# Spirit3 register map
File version: 1.0
CPU: CM0+ r0p0, little endian, no MPU, no FPU, 2 interrupt priority bits
Registers are 32-bit, read-write, reset 0x0 unless marked. A register's access mark holds for its fields unless they carry their own. Offsets are from the block's base; [hi:lo] are bit positions.

## BUBBLE_RF
Base 0x49001000
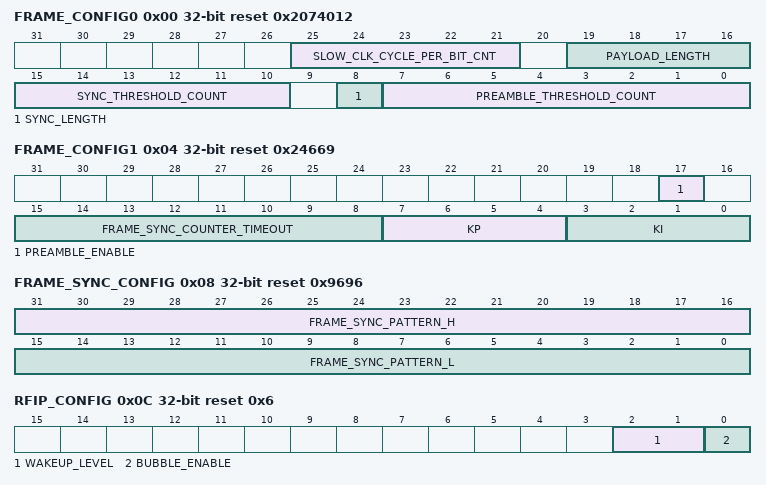
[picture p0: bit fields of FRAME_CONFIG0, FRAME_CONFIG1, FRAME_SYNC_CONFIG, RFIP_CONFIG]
0x00 FRAME_CONFIG0 reset 0x2074012
  [25:21] SLOW_CLK_CYCLE_PER_BIT_CNT — The number of expected slow clock cycle per each manchester coded bit (default 16)
  [19:16] PAYLOAD_LENGTH — The number of data Bytes in the payload (decoded)
  [15:10] SYNC_THRESHOLD_COUNT — Detection threshold when receiving the Frame sync (Manchester encoded)
  [8] SYNC_LENGTH — Frame sync pattern length
  [7:0] PREAMBLE_THRESHOLD_COUNT — the number of transitions for preamble detection when receiving the Manchester encoded preamble
0x04 FRAME_CONFIG1 reset 0x24669
  [17] PREAMBLE_ENABLE — Preamble detection enable
  [15:8] FRAME_SYNC_COUNTER_TIMEOUT — The timeout in Manchester encoded bits for the Frame Sync
  [7:4] KP — Kp is the first order gain value of the timing recovery loop
  [3:0] KI — Ki is the second order gain value of the timing recovery loop
0x08 FRAME_SYNC_CONFIG reset 0x9696
  [31:16] FRAME_SYNC_PATTERN_H — The value of the frame sync pattern, High word, Manchester encoded, used only when the frame sync length is 32 bits
  [15:0] FRAME_SYNC_PATTERN_L — The value of the frame sync pattern, Low word, Manchester encoded, used both when the frame sync length is 16 bits and 32 bits
0x0C RFIP_CONFIG reset 0x6
  [2:1] WAKEUP_LEVEL
  [0] BUBBLE_ENABLE — Enables (starts) or Disables (stops) the bubble feature
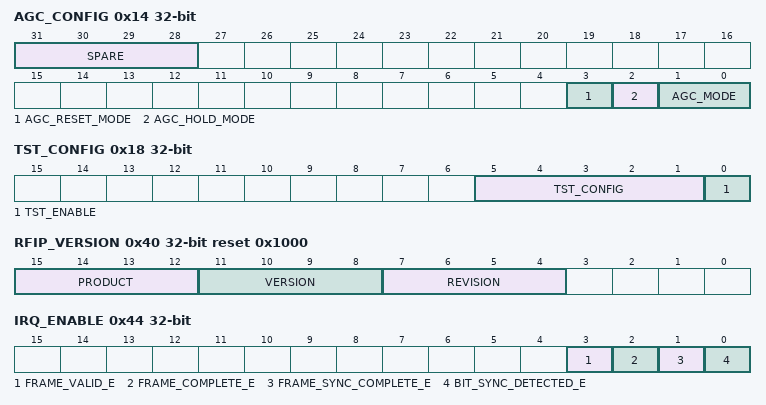
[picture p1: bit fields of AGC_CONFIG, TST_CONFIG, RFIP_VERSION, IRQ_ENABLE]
0x14 AGC_CONFIG
  [31:28] SPARE — SPARE registers
  [3] AGC_RESET_MODE — The AGC reset behavior when the AGC is working in ON or HOLD mode
  [2] AGC_HOLD_MODE — The behavior when the AGC is ON and is working in HOLD mode
  [1:0] AGC_MODE — Define the working mode of the AGC
0x18 TST_CONFIG
  [5:1] TST_CONFIG — Define which test configuration is reported in the DTB bus
  [0] TST_ENABLE — Enable (1) or Disable (0- default) the Test feature
0x1C PAYLOAD_0 ro
  [31:0] PAYLOAD_0 — First part of the payload (Least significant Byte First)
0x20 PAYLOAD_1 ro
  [31:0] PAYLOAD_1 — Second part of the payload (Least significant Byte First)
0x40 RFIP_VERSION ro reset 0x1000
  [15:12] PRODUCT — Used for major upgrades (new protocols support / new features)
  [11:8] VERSION — Version of the RFIP (to be used for cut upgrades)
  [7:4] REVISION — Revision of the RFIP to be used for metal fixes)
0x44 IRQ_ENABLE
  [3] FRAME_VALID_E — Enables interrupt on FRAME_VALID_F flag
  [2] FRAME_COMPLETE_E — Enables interrupt on FRMAE_COMPLETE_F flag
  [1] FRAME_SYNC_COMPLETE_E — Enables interrupt on FRAME_SYNC_COMPLETE_F flag
  [0] BIT_SYNC_DETECTED_E — Enables interrupt on BIT_SYNC_DETECTED_F flag
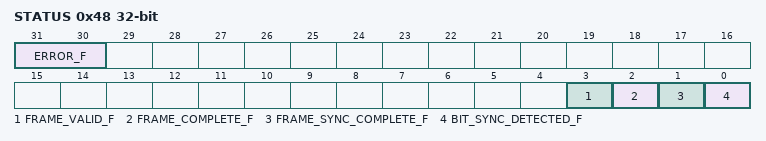
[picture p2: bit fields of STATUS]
0x48 STATUS
  [31:30] ERROR_F — error flag
  [3] FRAME_VALID_F — Frame (payload + CRC) received without error (the CRC has been checked and is matching with the received CRC)
  [2] FRAME_COMPLETE_F — Frame (payload + CRC) received, the content of the PAYLOAD_X registers is valid
  [1] FRAME_SYNC_COMPLETE_F — Frame Sync has been detected, the content of the PAYLOAD_X registers is not yet valid
  [0] BIT_SYNC_DETECTED_F — Preamble (= bit sync) has been detected, the content of the PAYLOAD_X registers is not yet valid

## COMP — Comparator instance 1
Base 0x40009000
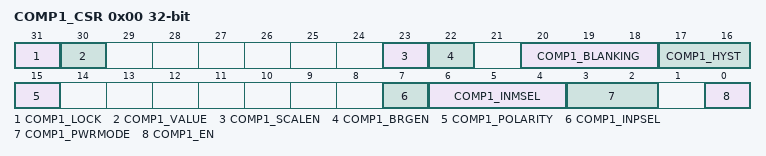
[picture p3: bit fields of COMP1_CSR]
0x00 COMP1_CSR access per field — Comparator control and status register
  [31] COMP1_LOCK rw — Comparator lock
  [30] COMP1_VALUE ro — Comparator output level
  [23] COMP1_SCALEN rw — Comparator scaler bridge enable
  [22] COMP1_BRGEN rw — Comparator voltage scaler enable
  [20:18] COMP1_BLANKING rw — Comparator blanking source
  [17:16] COMP1_HYST rw — Comparator hysteresis
  [15] COMP1_POLARITY rw — Comparator output polarity
  [7] COMP1_INPSEL rw — Comparator input plus selection
  [6:4] COMP1_INMSEL rw — Comparator input minus selection
  [3:2] COMP1_PWRMODE rw — Comparator power mode
  [0] COMP1_EN rw — Comparator enable
